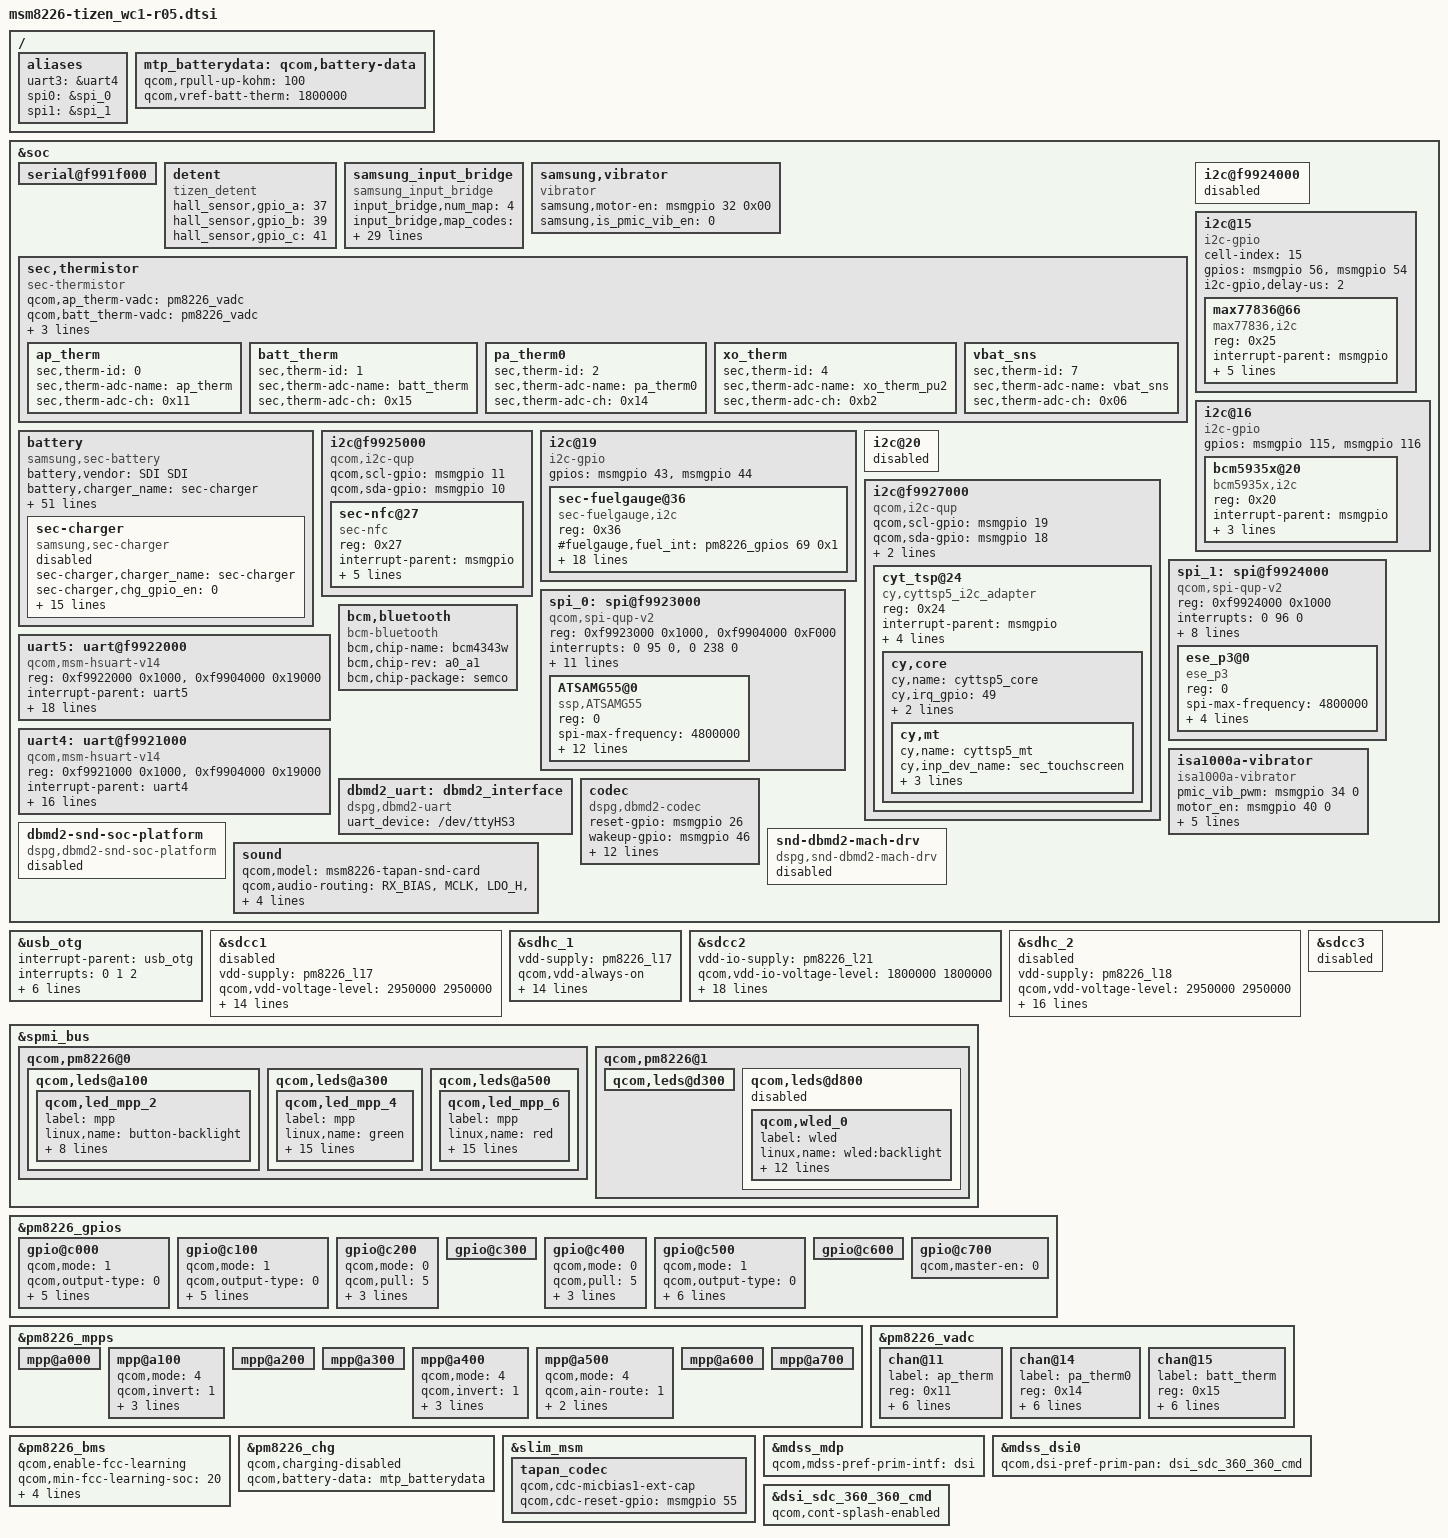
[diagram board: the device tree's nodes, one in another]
/* Copyright (c) 2013, The Linux Foundation. All rights reserved.
 *
 * This program is free software; you can redistribute it and/or modify
 * it under the terms of the GNU General Public License version 2 and
 * only version 2 as published by the Free Software Foundation.
 *
 * This program is distributed in the hope that it will be useful,
 * but WITHOUT ANY WARRANTY; without even the implied warranty of
 * MERCHANTABILITY or FITNESS FOR A PARTICULAR PURPOSE.  See the
 * GNU General Public License for more details.
 */

/{
	aliases {
		uart3 = &uart4;
		spi0 = &spi_0;
		spi1 = &spi_1;
	};
};

&soc {
	serial@f991f000 {
		status = "ok";
	};

	detent {
		compatible = "tizen_detent";
		hall_sensor,gpio_a = <37>;
		hall_sensor,gpio_b = <39>;
		hall_sensor,gpio_c = <41>;
	};

	samsung_input_bridge {
		compatible = "samsung_input_bridge";
		input_bridge,num_map = <4>;
		input_bridge,map_codes ="input_bridge,logdump_map_code",
					"input_bridge,safemode_map_code",
					"input_bridge,payment_map_code",
					"input_bridge,hall_log_map_code";
		input_bridge,map_types ="input_bridge,logdump_map_type",
					"input_bridge,safemode_map_type",
					"input_bridge,payment_map_type",
					"input_bridge,hall_log_map_type";
		input_bridge,logdump_map_code  = <115 114 115 114 116 114 115 116>;
		input_bridge,logdump_map_type  = <1 1 1 1 1 1 1 1>;
		input_bridge,safemode_map_code  = <114>;
		input_bridge,safemode_map_type  = <1>;
		input_bridge,payment_map_code  = <158>;
		input_bridge,payment_map_type  = <1>;
		input_bridge,hall_log_map_code = <116 8 8 8 8 8 8 8 8>;
		input_bridge,hall_log_map_type = <1 2 2 2 2 2 2 2 2>;
		input_bridge,env_str = "APPS_LOG", "SAFE_MODE", "PAYMENT", "APPS_LOG";
		input_bridge,env_value = "ON", "ON", "ON", "ON";
		input_bridge,map_key = <1>;
		input_bridge,enable_uevent = <1>;
		input_bridge,uevent_action = <2>;
		input_bridge,dev_num = <2>;
		input_bridge,dev_name_str = "qpnp_pon", "tizen_detent";
	};

	samsung,vibrator{
		compatible = "vibrator";
		samsung,motor-en = <&msmgpio 32 0x00>;
		samsung,is_pmic_vib_en = <0>;
		status = "ok";
	};

	sec,thermistor {
		compatible = "sec-thermistor";
		qcom,ap_therm-vadc	= <&pm8226_vadc>;
		qcom,batt_therm-vadc	= <&pm8226_vadc>;
		qcom,pa_therm0-vadc	= <&pm8226_vadc>;
		qcom,xo_therm_pu2-vadc	= <&pm8226_vadc>;
		qcom,vbat_sns-vadc	= <&pm8226_vadc>;
		ap_therm {
			sec,therm-id = <0>; /* SEC_THERM_AP */
			sec,therm-adc-name = "ap_therm";
			sec,therm-adc-ch = <0x11>; /* P_MUX_2_1_1 */
		};
		batt_therm {
			sec,therm-id = <1>; /* SEC_THERM_BATTERY */
			sec,therm-adc-name = "batt_therm";
			sec,therm-adc-ch = <0x15>; /* P_MUX_6_1_1 */
		};
		pa_therm0 {
			sec,therm-id = <2>; /* SEC_THERM_PAM0 */
			sec,therm-adc-name = "pa_therm0";
			sec,therm-adc-ch = <0x14>; /* P_MUX_5_1_1 */
		};
		xo_therm {
			sec,therm-id = <4>; /* SEC_THERM_XO */
			sec,therm-adc-name = "xo_therm_pu2";
			sec,therm-adc-ch = <0xb2>;
		};
		vbat_sns {
			sec,therm-id = <7>; /* SEC_THERM_VBAT_SNS */
			sec,therm-adc-name = "vbat_sns";
			sec,therm-adc-ch = <0x06>;
		};
	};

	battery {
		status = "okay";
		compatible = "samsung,sec-battery";
		battery,vendor = "SDI SDI";
		battery,charger_name = "sec-charger";
		battery,fuelgauge_name = "sec-fuelgauge";
		/* POWER_SUPPLY_TECHNOLOGY_LION */
		battery,technology = <2>;
		battery,bat_gpio_ta_nconnected = <2>;
		battery,chip_vendor = "QCOM";
		battery,bat_irq = <0>;
		battery,bat_irq_attr = <0>;
		/* SEC_BATTERY_CABLE_CHECK_CHGINT */
		battery,cable_check_type = <16>;
		/* SEC_BATTERY_CABLE_SOURCE_EXTERNAL */
		battery,cable_source_type = <1>;
		battery,event_check = <1>; /* true */
		battery,event_waiting_time = <180>;
		/* Monitor Setting */
		/* SEC_BATTERY_MONITOR_ALARM */
		battery,polling_type = <1>;
		battery,monitor_initial_count = <3>;
		/* SEC_BATTERY_CHECK_NONE */
		battery,battery_check_type = <0>;
		battery,check_count = <0>;
		battery,check_adc_max = <1440>;
		battery,check_adc_min = <0>;
		/* SEC_BATTERY_OVP_UVLO_CHGPOLLING */
		battery,ovp_uvlo_check_type = <3>;
		/* SEC_BATTERY_THERMAL_SOURCE_ADC */
		battery,thermal_source = <2>;
		battery,temp_adc_type = <1>; /* SEC_BATTERY_ADC_TYPE_AP */
		battery,adc_type = <0 1 1 1 1>; /* SEC_BATTERY_ADC_TYPE_AP */
		/* Basic - 10s, Charging - 30s, Dis-Charging - 30s,
		   30 - Not Charging, Sleep - 3600
		 */
		battery,polling_time = <10 30 30 30 3600>;
		battery,adc_check_count = <6>;
		/* battery,temp_table_adc = <27281 27669 28178 28724 29342
		   30101 30912 31807 32823 33858 34950 36049 37054 38025 38219
		   38448 38626 38795 38989 39229 39540 39687
		   39822 40523 41123 41619>;
		 */
		/* Temperature related information */
		/* SEC_BATTERY_TEMP_CHECK_NONE */
		battery,temp_check_type = <0>;
		battery,temp_check_count = <1>;
		battery,temp_high_threshold_event = <580>;
		battery,temp_high_recovery_event = <530>;
		battery,temp_low_threshold_event = <(-50)>;
		battery,temp_low_recovery_event = <0>;
		battery,temp_high_threshold_normal = <580>;
		battery,temp_high_recovery_normal = <530>;
		battery,temp_low_threshold_normal = <(-50)>;
		battery,temp_low_recovery_normal = <0>;

		battery,temp_high_threshold_lpm = <580>;
		battery,temp_high_recovery_lpm = <530>;
		battery,temp_low_threshold_lpm = <(-50)>;
		battery,temp_low_recovery_lpm = <0>;

		/* Battery - Charging Scenario */
		/* SEC_BATTERY_FULLCHARGED_CHGPSY */
		battery,full_check_type = <7>;
		/* SEC_BATTERY_FULLCHARGED_TIME */
		battery,full_check_type_2nd = <3>;
		battery,full_check_count = <1>;
		battery,chg_gpio_full_check = <0>;
		battery,chg_polarity_full_check = <1>;

		/* SEC_BATTERY_FULL_CONDITION_SOC |
		   SEC_BATTERY_FULL_CONDITION_NOTIMEFULL |
		   SEC_BATTERY_FULL_CONDITION_VCELL
		 */
		battery,full_condition_type = <13>;
		battery,full_condition_soc = <97>;
		battery,full_condition_vcell = <4300>;

		battery,recharge_check_count = <2>;
		/* SEC_BATTERY_RECHARGE_CONDITION_VCELL */
		battery,recharge_condition_type = <4>;
		battery,recharge_condition_soc = <90>;
		battery,recharge_condition_vcell = <4300>;

		battery,charging_total_time = <21600>; /* 6 Hours */
		battery,recharging_total_time = <5400>; /* 1.5 Hours */
		battery,charging_reset_time = <0>;

		/* Values need to be confirmed with the 8x26 H/W */
		/* Current related parameters need to be verified hence DT
		   for charger is not being used
		 */
		sec-charger{
			status = "disable";
			/* Charger */
			compatible = "samsung,sec-charger";
			sec-charger,charger_name = "sec-charger";
			sec-charger,chg_gpio_en = <0>;
			sec-charger,chg_polarity_en = <0>;
			sec-charger,chg_gpio_status = <0>;
			sec-charger,chg_polarity_status = <0>;
			sec-charger,chg_irq = <0>;
			sec-charger,chg_float_voltage = <4350>;
			/* SEC_BATTERY_OVP_UVLO_CHGPOLLING */
			sec-charger,ovp_uvlo_check_type = <3>;
			/* SEC_BATTERY_FULLCHARGED_CHGPSY */
			sec-charger,full_check_type = <7>;
			sec-charger,input_current_limit = <1800 460 460 1800 460
				900 1000 460 460 1000 650 1800 1800 460
				400 700 1300 300 1000 1800 460>;
			sec-charger,fast_charging_current = <2100 0 460 2100 460
				1200 1000 460 0 1200 750 2100 2100 0 400 700
				1300 300 1000 2100 0>;
			sec-charger,full_check_current_1st = <200 0 200 200 200
				200 200 200 0 200 200 200 200
				0 200 200 200 200 200 200 0>;
			sec-charger,full_check_current_2nd = <2400 0 2400 1800
				2400 2400 2400 2400 0 2400 2400
				2400 2400 0 2400 2400 2400 2400 2400 2400 0>;
		};
	};

	i2c@f9924000 {
	    status = "disable";
	};

	i2c@15{ /*BLSP-1 QUP-4*/
		/*MAX77836 Chip Node*/
		cell-index = <15>;
		compatible = "i2c-gpio";
		gpios = <&msmgpio 56 0  /*SDA*/
			&msmgpio 54 0 >;/*SCL*/
		i2c-gpio,delay-us = <2>;
		#address-cells = <1>;
		#size-cells = <0>;
		max77836@66 {
			compatible = "max77836,i2c";
			reg = <0x25>;
			interrupt-parent = <&msmgpio>;
			interrupts = <52 0>;
			max77836,irq-gpio = <&msmgpio 52 0x00>;
			max77836,irq-base = <353>;
			max77836,wc-irq-gpio = <0>;
			max77836,wakeup = <1>;
		};
	};

	i2c@16 {
		compatible = "i2c-gpio";
		gpios = <&msmgpio 115 0 /* sda */
			&msmgpio 116 0 /* scl */
			>;
		#address-cells = <1>;
		#size-cells = <0>;
		bcm5935x@20 {
			compatible = "bcm5935x,i2c";
			reg = <0x20>;
			interrupt-parent = <&msmgpio>;
			interrupts = <67 0>;
			bcm-wpc,irq-gpio = <&msmgpio 67 0x0>;
			bcm-wpc,detect_type = <0>;
		};
	};
	
	i2c@f9925000 {
		compatible = "qcom,i2c-qup";
		qcom,scl-gpio = <&msmgpio 11 0>;/* sda */
		qcom,sda-gpio = <&msmgpio 10 0>;/* scl */
		sec-nfc@27 {
			compatible = "sec-nfc";
			reg = <0x27>;
			interrupt-parent = <&msmgpio>;
			interrupts = <72 0>;
			sec-nfc,ven-gpio = <&msmgpio 45 0x0>;
			sec-nfc,firm-gpio = <&msmgpio 42 0x0>;
			sec-nfc,irq-gpio = <&msmgpio 72 0x0>;
			sec-nfc,pvdd-gpio = <&msmgpio 35 0x0>;
		};
	};

	i2c@19 {
		compatible = "i2c-gpio";
		gpios = <&msmgpio 43 0 /* sda */
			&msmgpio 44 0 /* scl */
			>;
		#address-cells = <1>;
		#size-cells = <0>;
		sec-fuelgauge@36 {
			compatible = "sec-fuelgauge,i2c";
			reg = <0x36>;
			#fuelgauge,fuel_int = <&pm8226_gpios 69 0x1>;
			interrupt-parent = <&msmgpio>;
			interrupts = <69 0>;
			fuelgauge,fuel_int = <&msmgpio 69 0x0>;
			fuelgauge,fg_irq = <&msmgpio 69 0x0>;
			/* IRQF_TRIGGER_RISING */
			fg_irq_attr = <1>;
			fuelgauge,fuel_alert_soc = <2>;
			fuelgauge,repeated_fuelalert = <0>;
			/* fuelgauge,bat_int = <&pm8226_mpps 8 0>; */
			fuelgauge,bat_irq = <0>;
			/* .capacity_calculation_type =
			   SEC_FUELGAUGE_CAPACITY_TYPE_RAW |
			   SEC_FUELGAUGE_CAPACITY_TYPE_SCALE |
			   SEC_FUELGAUGE_CAPACITY_TYPE_DYNAMIC_SCALE |
			   SEC_FUELGAUGE_CAPACITY_TYPE_SKIP_ABNORMAL,
			 */
			/* fuelgauge,capacity_calculation_type = <0x17>; */
			fuelgauge,capacity_calculation_type = <0x07>;
			fuelgauge,capacity_max = <1000>;
			fuelgauge,capacity_max_margin = <50>;
			fuelgauge,capacity_min = <5>;
			/*
			   fuelgauge,rcomp0 = <0x7B>;
			   fuelgauge,rcomp_charging = <0x79>;
			 */
			fuelgauge,rcomp0 = <0x4A>;
			fuelgauge,rcomp_charging = <0x4A>;
			fuelgauge,temp_cohot = <0xFFFFFAD2>; 	/* -1325 */
			fuelgauge,temp_cocold = <0xFFFFE93E>;	/* -5825 */
			/* using 19 bits as recommended by Maxim */
			fuelgauge,is_using_model_data = <1>;
			fuelgauge,type_str = "SDI";
		};
	};

	i2c@20 {
		status="disabled";
	};

	i2c@f9927000{ /* BLSP1 QUP5 Hardware ID BLSP5 */
		compatible = "qcom,i2c-qup";
		qcom,scl-gpio = <&msmgpio 19 0>;
		qcom,sda-gpio = <&msmgpio 18 0>;
		qcom,i2c-bus-freq = <400000>;
		qcom,clk-ctl-xfer;
		cyt_tsp@24 {
			compatible = "cy,cyttsp5_i2c_adapter";
			reg = <0x24>; /*slave address*/
			interrupt-parent = <&msmgpio>;
			interrupts = <49 0>;
			vddo-supply = <&pm8226_l28>;
			avdd-supply = <&pm8226_l19>;

			cy,adapter_id = "cyttsp5_i2c_adapter";
			cy,core {
				cy,name = "cyttsp5_core";
				cy,irq_gpio = <49>;
				cy,hid_desc_register = <1>;
				cy,report_rate = <90>;
				cy,mt {
					cy,name = "cyttsp5_mt";
					cy,inp_dev_name = "sec_touchscreen";
					cy,flags = <0x00>;
					cy,abs =
						/* ABS_MT_POSITION_X, CY_ABS_MIN_X, CY_ABS_MAX_X, 0, 0 */
						<0x35 0 360 0 0
						/* ABS_MT_POSITION_Y, CY_ABS_MIN_Y, CY_ABS_MAX_Y, 0, 0 */
						0x36 0 360 0 0
						/* ABS_MT_PRESSURE, CY_ABS_MIN_P, CY_ABS_MAX_P, 0, 0 */
						0x3a 0 255 0 0
						/* CY_IGNORE_VALUE, CY_ABS_MIN_W, CY_ABS_MAX_W, 0, 0 */
						0xffff 0 255 0 0
						/* ABS_MT_TRACKING_ID, CY_ABS_MIN_T, CY_ABS_MAX_T, 0, 0 */
						0x39 0 15 0 0
						/* ABS_MT_TOUCH_MAJOR, 0, 255, 0, 0 */
						0x30 0 255 0 0
						/* ABS_MT_TOUCH_MINOR, 0, 255, 0, 0 */
						0x31 0 255 0 0
						/* ABS_MT_ORIENTATION, -128, 127, 0, 0 */
						0x34 0xfffffed7 127 0 0
						/* ABS_MT_TOOL_TYPE, 0, MT_TOOL_MAX, 0, 0 */
						0x37 0 1 0 0>;
				};
			};
		};
	};

	spi_0: spi@f9923000 { /* BLSP1 BLSP1_QUP0*/
		compatible = "qcom,spi-qup-v2";
		#address-cells = <1>;
		#size-cells = <0>;
		reg-names = "spi_physical", "spi_bam_physical";
		reg = <0xf9923000 0x1000>,
			<0xf9904000 0xF000>;
		interrupt-names = "spi_irq", "spi_bam_irq";
		interrupts = <0 95 0>, <0 238 0>;
		spi-max-frequency = <19200000>;

		qcom,gpio-mosi = <&msmgpio 0 0>;
		qcom,gpio-miso = <&msmgpio 1 0>;
		qcom,gpio-clk  = <&msmgpio 3 0>;
		qcom,gpio-cs0  = <&msmgpio 2 0>;

		qcom,infinite-mode = <0>;
		qcom,use-bam;
		qcom,ver-reg-exists;
		qcom,bam-consumer-pipe-index = <12>;
		qcom,bam-producer-pipe-index = <13>;
		qcom,master-id = <86>;

		ATSAMG55@0 {
			compatible = "ssp,ATSAMG55";
			reg = <0>;
			spi-max-frequency = <4800000>;
			interrupt-parent = <&msmgpio>;
			interrupts = <106 0>;
			ssp,mcu_int1-gpio = <&msmgpio 106 0x00>;
			ssp,mcu_int2-gpio = <&msmgpio 107 0x00>;
			ssp,ap_int-gpio = <&msmgpio 108 0x00>;
			ssp,rst-gpio = <&msmgpio 28 0x00>;
			ssp,acc-position = <4>;
			ssp,mag-position = <2>;
			ssp,ap-rev=<5>;
			ssp,fw_name = "ssp_wc1-l.fw";
			ssp,ums_fw_name = "ssp_at.bin";
			ssp,mcu_vreg-supply = <&pm8226_lvs1>;
		};
	};

        spi_1: spi@f9924000 { /* BLSP2 BLSP1_QUP1*/
                compatible = "qcom,spi-qup-v2";
                #address-cells = <1>;
                #size-cells = <0>;
                reg-names = "spi_physical";
                reg = <0xf9924000 0x1000>;
                interrupt-names = "spi_irq";
                interrupts = <0 96 0>;
                spi-max-frequency = <19200000>;

                qcom,gpio-mosi = <&msmgpio 4 0>;
                qcom,gpio-miso = <&msmgpio 5 0>;
                qcom,gpio-clk  = <&msmgpio 7 0>;
                qcom,gpio-cs0  = <&msmgpio 6 0>;

                qcom,infinite-mode = <0>;
                qcom,ver-reg-exists;
                qcom,master-id = <86>;

		ese_p3@0 {
		    compatible = "ese_p3";
		    reg = <0>;
		    spi-max-frequency = <4800000>;
		    p3-cs-gpio = <&msmgpio 6 0>;
		    p3-clk-gpio = <&msmgpio 7 0>;
		    p3-mosi-gpio = <&msmgpio 4 0>;
		    p3-miso-gpio = <&msmgpio 5 0>;
		};
	};


	uart5: uart@f9922000 { /* BLSP1 UART5 : HW ID BLSP6 */
		       compatible = "qcom,msm-hsuart-v14";
		       status = "ok";
		       reg = <0xf9922000 0x1000>,
			   <0xf9904000 0x19000>;
		       reg-names = "core_mem", "bam_mem";
		       interrupt-names = "core_irq", "bam_irq", "wakeup_irq";
		#address-cells = <0>;
		       interrupt-parent = <&uart5>;
		       interrupts = <0 1 2>;
		#interrupt-cells = <1>;
		       interrupt-map-mask = <0xffffffff>;
		       interrupt-map = <0 &intc 0 112 0
			       1 &intc 0 238 0
			       2 &msmgpio 21 0>;
		       qcom,tx-gpio = <&msmgpio 20 0x00>;
		       qcom,rx-gpio = <&msmgpio 21 0x00>;
		       qcom,cts-gpio = <&msmgpio 22 0x00>;
		       qcom,rfr-gpio = <&msmgpio 23 0x00>;
		       qcom,inject-rx-on-wakeup = <1>;
		       qcom,rx-char-to-inject = <0xFD>;
		       qcom,msm-obs = <1>; /* for case 01545094 */

		       qcom,bam-tx-ep-pipe-index = <10>;		/*Consumer pipe*/
		       qcom,bam-rx-ep-pipe-index = <11>;		/*Producer pipe*/
		       qcom,msm-bus,name = "uart5";
		       qcom,msm-bus,num-cases = <2>;
		       qcom,msm-bus,num-paths = <1>;
		       qcom,msm-bus,vectors-KBps = <86 512 0 0>,
			       <86 512 500 800>;
	};

	uart4: uart@f9921000 { /* BLSP1 UART4 : HW ID BLSP5 */
			compatible = "qcom,msm-hsuart-v14";
			status = "ok";
			reg = <0xf9921000 0x1000>,
				<0xf9904000 0x19000>;
			reg-names = "core_mem", "bam_mem";
			interrupt-names = "core_irq", "bam_irq", "wakeup_irq";
			#address-cells = <0>;
			interrupt-parent = <&uart4>;
			interrupts = <0 1 2>;
			#interrupt-cells = <1>;
			interrupt-map-mask = <0xffffffff>;
			interrupt-map = <0 &intc 0 111 0 1 &intc 0 238 0 2 &msmgpio 17 0>;
			qcom,tx-gpio = <&msmgpio 16 0x00>;
			qcom,rx-gpio = <&msmgpio 17 0x00>;
			qcom,inject-rx-on-wakeup = <1>;
			qcom,rx-char-to-inject = <0xFD>;
			qcom,msm-obs = <1>; /* for case 01545094 */
			qcom,bam-tx-ep-pipe-index = <8>;
			qcom,bam-rx-ep-pipe-index = <9>;
			qcom,msm-bus,name = "uart4";
			qcom,msm-bus,num-cases = <2>;
			qcom,msm-bus,num-paths = <1>;
			qcom,msm-bus,vectors-KBps = <86 512 0 0>, <86 512 500 800>;
	};

	isa1000a-vibrator {
		status = "okay";
		compatible = "isa1000a-vibrator";
		pmic_vib_pwm = <&msmgpio 34 0>;
		motor_en = <&msmgpio 40 0>;
		/*compatible = "vibrator";*/
		pinctrl-names = "default";
		haptic,max_timeout = <10000>;
		haptic,duty = <32580>;
		haptic,period = <33244>;
		haptic,pwm_id = <0>;
		/*haptic,regulator_name = "VDD_MOTOR_3V0";*/
		haptic,regulator_name = "mot_3.3v";
	};

	bcm,bluetooth {
		compatible = "bcm-bluetooth";
		bcm,chip-name = "bcm4343w";
		bcm,chip-rev = "a0_a1";
		bcm,chip-package = "semco";
	};

	dbmd2_uart: dbmd2_interface {
		status = "okay";
		compatible = "dspg,dbmd2-uart";
		uart_device = "/dev/ttyHS3";
	};

	codec {
		status = "okay";
		compatible = "dspg,dbmd2-codec";
		reset-gpio = <&msmgpio 26 0>;
		wakeup-gpio = <&msmgpio 46 0>; /* chip enable */
		sv-gpio = <&msmgpio 27 0>; /* voice interrupt */

		cmd-interface = <&dbmd2_uart>;
		feature-va; /* enable VA */
		va-firmware-name = "dbmd2_va_fw.bin";
		va-config = <0x80220103
				0x8015008a
				0x801b0020
				0x80210000
				0x80290001
				0x80230040
				0x8016000a
				0x80280301>;
		va-speeds = <0x0301 57600 0 0
			     0x0000 1000000 0 0
			     0x0000 1000000 0 0>;

		va-mic-config = <0x0001 0x0002 0x004d>;
		va-mic-mode = <4>;
		auto_detection = <1>;
		master-clk-rate = <32768>;
	};

	dbmd2-snd-soc-platform {
		status = "disable";
		compatible = "dspg,dbmd2-snd-soc-platform";
	};

	snd-dbmd2-mach-drv {
		status = "disable";
		compatible = "dspg,snd-dbmd2-mach-drv";
	};

	sound {
		qcom,model = "msm8226-tapan-snd-card";
		qcom,audio-routing =
			"RX_BIAS", "MCLK",
			"LDO_H", "MCLK",
			"SPK_OUT", "MCLK",
			"SPK_OUT", "EXT_VDD_SPKR",
			"AMIC1", "External LDO",
			"External LDO", "Main Mic";

		qcom,cdc-mclk-gpios = <&pm8226_gpios 1 0>;
		qcom,micbias-en-gpio = <&pm8226_gpios 6 0>;
		/*qcom,cdc-vdd-spkr-gpios = <&pm8226_gpios 2 0>;*/
	};
};

&usb_otg {
	#address-cells = <0>;
	interrupt-parent = <&usb_otg>;
	interrupts = <0 1 2>;
	#interrupt-cells = <1>;
	interrupt-map-mask = <0xffffffff>;
	interrupt-map = <0 &intc 0 134 0
			1 &intc 0 140 0
			2 &spmi_bus 0x0 0x0 0x9 0x0>;
	interrupt-names = "core_irq", "async_irq", "pmic_id_irq";

	qcom,hsusb-otg-mode = <1>;
	qcom,hsusb-otg-otg-control = <2>;
	vbus_otg-supply = <&pm8226_chg_otg>;
};

&sdcc1 {
	vdd-supply = <&pm8226_l17>;
	qcom,vdd-voltage-level = <2950000 2950000>;
	qcom,vdd-current-level = <800 500000>;

	vdd-io-supply = <&pm8226_l6>;
	qcom,vdd-io-always-on;
	qcom,vdd-io-voltage-level = <1800000 1800000>;
	qcom,vdd-io-current-level = <250 154000>;

	qcom,pad-pull-on = <0x0 0x3 0x3>; /* no-pull, pull-up, pull-up */
	qcom,pad-pull-off = <0x0 0x3 0x3>; /* no-pull, pull-up, pull-up */
	qcom,pad-drv-on = <0x4 0x4 0x4>; /* 10mA, 10mA, 10mA */
	qcom,pad-drv-off = <0x0 0x0 0x0>; /* 2mA, 2mA, 2mA */

	qcom,clk-rates = <400000 25000000 50000000 100000000 200000000>;
	qcom,sup-voltages = <2950 2950>;

	qcom,bus-speed-mode = "HS200_1p8v", "DDR_1p8v";
	qcom,nonremovable;

	status = "disabled";
};

&sdhc_1 {
	vdd-supply = <&pm8226_l17>;
	qcom,vdd-always-on;
	qcom,vdd-voltage-level = <2950000 2950000>;
	qcom,vdd-current-level = <800 500000>;

	vdd-io-supply = <&pm8226_l6>;
	qcom,vdd-io-always-on;
	qcom,vdd-io-voltage-level = <1800000 1800000>;
	qcom,vdd-io-current-level = <250 154000>;

	qcom,pad-pull-on = <0x0 0x3 0x3>; /* no-pull, pull-up, pull-up */
	qcom,pad-pull-off = <0x0 0x3 0x3>; /* no-pull, pull-up, pull-up */
	qcom,pad-drv-on = <0x4 0x4 0x4>; /* 10mA, 10mA, 10mA */
	qcom,pad-drv-off = <0x0 0x0 0x0>; /* 2mA, 2mA, 2mA */

	qcom,clk-rates = <400000 25000000 50000000 100000000 200000000>;
	qcom,bus-speed-mode = "HS200_1p8v", "DDR_1p8v";
	qcom,nonremovable;

	status = "ok";
};

&sdcc2 {
	vdd-io-supply = <&pm8226_l21>;
	qcom,vdd-io-voltage-level = <1800000 1800000>;
	qcom,vdd-io-current-level = <2000 16000>;
	qcom,vdd-io-always-on;

	qcom,pad-pull-on = <0x0 0x3 0x3>; /* no-pull, pull-up, pull-up */
	qcom,pad-pull-off = <0x0 0x3 0x3>; /* no-pull, pull-up, pull-up */
	qcom,pad-drv-on = <0x4 0x4 0x4>; /* 10mA, 10mA, 10mA */
	qcom,pad-drv-off = <0x0 0x0 0x0>; /* 2mA, 2mA, 2mA */

	qcom,clk-rates = <400000 25000000 50000000 100000000 200000000>;
	qcom,sup-voltages = <2950 2950>;

	qcom,xpc;
	qcom,bus-speed-mode = "SDR12", "SDR25", "SDR50", "DDR50", "SDR104";
	qcom,current-limit = <600>; #address-cells = <0>; interrupt-parent = <&sdcc2>;
	interrupts = <0 1 2>;
	#interrupt-cells = <1>;
	interrupt-map-mask = <0xffffffff>;
	interrupt-map = <0 &intc 0 125 0
			1 &intc 0 220 0>;
	interrupt-names = "core_irq", "bam_irq";
	status-cb = <2>;

	status = "ok";
};

&sdhc_2 {
	vdd-supply = <&pm8226_l18>;
	qcom,vdd-voltage-level = <2950000 2950000>;
	qcom,vdd-current-level = <9000 800000>;

	vdd-io-supply = <&pm8226_l21>;
	qcom,vdd-io-voltage-level = <1800000 2950000>;
	qcom,vdd-io-current-level = <6 22000>;

	qcom,pad-pull-on = <0x0 0x3 0x3>; /* no-pull, pull-up, pull-up */
	qcom,pad-pull-off = <0x0 0x3 0x3>; /* no-pull, pull-up, pull-up */
	qcom,pad-drv-on = <0x4 0x4 0x4>; /* 10mA, 10mA, 10mA */
	qcom,pad-drv-off = <0x0 0x0 0x0>; /* 2mA, 2mA, 2mA */

	qcom,clk-rates = <400000 25000000 50000000 100000000 200000000>;

	#address-cells = <0>;
	interrupt-parent = <&sdhc_2>;
	interrupts = <0 1 2>;
	#interrupt-cells = <1>;
	interrupt-map-mask = <0xffffffff>;
	interrupt-map = <0 &intc 0 125 0
			1 &intc 0 221 0
			2 &msmgpio 38 0x3>;
	interrupt-names = "hc_irq", "pwr_irq", "status_irq";
	cd-gpios = <&msmgpio 38 0x1>;

	status = "disabled";
};

&sdcc3 {
	status = "disabled";
};

&spmi_bus {
	qcom,pm8226@0 {
		qcom,leds@a100 {
			status = "okay";
			qcom,led_mpp_2 {
				label = "mpp";
				linux,name = "button-backlight";
				linux,default-trigger = "none";
				qcom,default-state = "off";
				qcom,max-current = <40>;
				qcom,current-setting = <5>;
				qcom,id = <6>;
				qcom,mode = "manual";
				qcom,source-sel = <1>;
				qcom,mode-ctrl = <0x60>;
			};
		};

		qcom,leds@a300 {
			status = "okay";
			qcom,led_mpp_4 {
				label = "mpp";
				linux,name = "green";
				linux,default-trigger = "battery-full";
				qcom,default-state = "off";
				qcom,max-current = <40>;
				qcom,current-setting = <5>;
				qcom,id = <6>;
				qcom,mode = "pwm";
				qcom,pwm-us = <1000>;
				qcom,source-sel = <8>;
				qcom,mode-ctrl = <0x60>;
				qcom,pwm-channel = <0>;
				qcom,start-idx = <1>;
				qcom,ramp-step-ms = <120>;
				qcom,duty-pcts = [00 00 00 00 00
						  00 00 00 00 00
						  50 00 00 00 00
						  00 00 00 00 00
						  00];
				qcom,use-blink;
			};
		};

		qcom,leds@a500 {
			status = "okay";
			qcom,led_mpp_6 {
				label = "mpp";
				linux,name = "red";
				linux,default-trigger = "battery-charging";
				qcom,default-state = "off";
				qcom,max-current = <40>;
				qcom,current-setting = <5>;
				qcom,id = <6>;
				qcom,mode = "pwm";
				qcom,pwm-us = <1000>;
				qcom,mode-ctrl = <0x60>;
				qcom,source-sel = <10>;
				qcom,pwm-channel = <5>;
				qcom,start-idx = <1>;
				qcom,ramp-step-ms = <120>;
				qcom,duty-pcts = [00 00 00 00 00
						  00 00 00 00 00
						  50 00 00 00 00
						  00 00 00 00 00
						  00];
				qcom,use-blink;
			};
		};
	};

	qcom,pm8226@1 {
		qcom,leds@d300 {
			status = "okay";
		};

		qcom,leds@d800 {
			status = "disabled"; /*If WLED is not used for Backlight control*/
			qcom,wled_0 {		/*for TFT Panel, this to be disabled */
				label = "wled";
				linux,name = "wled:backlight";
				linux,default-trigger = "bkl-trigger";
				qcom,cs-out-en;
				qcom,op-fdbck = <1>;
				qcom,default-state = "off";
				qcom,max-current = <20>;
				qcom,ctrl-delay-us = <0>;
				qcom,boost-curr-lim = <3>;
				qcom,cp-sel = <0>;
				qcom,switch-freq = <11>;
				qcom,ovp-val = <0>;
				qcom,num-strings = <1>;
				qcom,id = <0>;
			};
		};
	};
};

&pm8226_gpios {
	gpio@c000 { /* GPIO 1 */
		/* XO_PMIC_CDC_MCLK enable for tapan codec */
		qcom,mode = <1>;		/* Digital output */
		qcom,output-type = <0>;	/* CMOS logic */
		qcom,pull = <5>;		/* QPNP_PIN_PULL_NO*/
		qcom,vin-sel = <3>;		/* QPNP_PIN_VIN3 */
		qcom,out-strength = <3>;/* QPNP_PIN_OUT_STRENGTH_HIGH */
		qcom,src-sel = <2>;		/* QPNP_PIN_SEL_FUNC_1 */
		qcom,master-en = <1>;	/* Enable GPIO */
	};

	gpio@c100 { /* GPIO 2 */
		qcom,mode = <1>;
		qcom,output-type = <0>;
		qcom,pull = <5>;
		qcom,vin-sel = <3>;
		qcom,out-strength = <3>;
		qcom,src-sel = <2>;
		qcom,master-en = <1>;
	};

	gpio@c200 { /* GPIO 3 */
		qcom,mode = <0>;		/* Digital intput */
		/*qcom,output-type = <0>;*/
		/* CMOS logic */
		qcom,pull = <5>;		/* QPNP_PIN_PULL_NO*/
		qcom,vin-sel = <2>;		/* QPNP_PIN_VIN3 */ /*3*/
		qcom,src-sel = <2>;		/* QPNP_PIN_SEL_FUNC_1 */
		qcom,master-en = <1>;	/* Enable GPIO */
	};

	gpio@c300 { /* GPIO 4 */
	};

	gpio@c400 { /* GPIO 5 */
		qcom,mode = <0>;		/* QPNP_PIN_MODE_DIG_IN */
		qcom,pull = <5>;		/* QPNP_PIN_PULL_NO */
		qcom,vin-sel = <2>;		/* QPNP_PIN_VIN2 */
		qcom,src-sel = <2>;		/* QPNP_PIN_SEL_FUNC_1 */
		qcom,master-en = <1>;
	};

	gpio@c500 { /* GPIO 6 */
		qcom,mode = <1>;                /* Digital output */
		qcom,output-type = <0>;         /* CMOS logic */
		qcom,pull = <5>;                /* QPNP_PIN_PULL_NO */
		qcom,invert = <0>;              /* Output low initially */
		qcom,vin-sel = <2>;             /* S3 = 1.8 V */
		qcom,src-sel = <0>;             /* Constant */
		qcom,out-strength = <2>;        /* Medium drive strength */
		qcom,master-en = <1>;           /* Enable GPIO */
	};

	gpio@c600 { /* GPIO 7 */
	};

	gpio@c700 { /* GPIO 8 */
		qcom,master-en = <0>;
	};
};

&pm8226_mpps {
	mpp@a000 { /* MPP 1 */
	};

	mpp@a100 { /* MPP 2 */
		/* AP_THERM config */
		qcom,mode = <4>; /* AIN input */
		qcom,invert = <1>; /* Enable MPP */
		qcom,ain-route = <1>; /* AMUX 6 */
		qcom,master-en = <1>;
		qcom,src-sel = <0>; /* Function constant */
	};

	mpp@a200 { /* MPP 3 */
	};

	mpp@a300 { /* MPP 4 */
	};

	mpp@a400 { /* MPP 5 */
		/* PA_THERM0 config */
		qcom,mode = <4>; /* AIN input */
		qcom,invert = <1>; /* Enable MPP */
		qcom,ain-route = <0>; /* AMUX 5 */
		qcom,master-en = <1>;
		qcom,src-sel = <0>; /* Function constant */
	};

	mpp@a500 { /* MPP 6 */
		/* BATT_THERM config */
		qcom,mode = <4>; /* AIN input */
		qcom,ain-route = <1>; /* AMUX 6 */
		qcom,master-en = <1>;
		qcom,src-sel = <0>; /* Function constant */
	};

	mpp@a600 { /* MPP 7 */
	};

	mpp@a700 { /* MPP 8 */
	};
};

&pm8226_vadc {
	chan@11 {
		label = "ap_therm";
		reg = <0x11>;
		qcom,decimation = <0>;
		qcom,pre-div-channel-scaling = <0>;
		qcom,calibration-type = "ratiometric";
		qcom,scale-function = <2>;
		qcom,hw-settle-time = <2>;
		qcom,fast-avg-setup = <0>;
	};

	chan@14 {
		label = "pa_therm0";
		reg = <0x14>;
		qcom,decimation = <0>;
		qcom,pre-div-channel-scaling = <0>;
		qcom,calibration-type = "ratiometric";
		qcom,scale-function = <10>;
		qcom,hw-settle-time = <2>;
		qcom,fast-avg-setup = <0>;
	};

	chan@15 {
		label = "batt_therm";
		reg = <0x15>;
		qcom,decimation = <0>;
		qcom,pre-div-channel-scaling = <0>;
		qcom,calibration-type = "ratiometric";
		qcom,scale-function = <2>;
		qcom,hw-settle-time = <2>;
		qcom,fast-avg-setup = <0>;
	};
};

/ {
	mtp_batterydata: qcom,battery-data {
		qcom,rpull-up-kohm = <100>;
		qcom,vref-batt-therm = <1800000>;

		/include/ "batterydata-palladium.dtsi"
		/include/ "batterydata-mtp-3000mah.dtsi"
	};
};

&pm8226_bms {
	status = "ok";
	qcom,enable-fcc-learning;
	qcom,min-fcc-learning-soc = <20>;
	qcom,min-fcc-ocv-pc = <30>;
	qcom,min-fcc-learning-samples = <5>;
	qcom,fcc-resolution = <10>;
	qcom,battery-data = <&mtp_batterydata>;
};

&pm8226_chg {
	qcom,charging-disabled;
	qcom,battery-data = <&mtp_batterydata>;
};

&slim_msm {
	tapan_codec {
		qcom,cdc-micbias1-ext-cap;
		qcom,cdc-reset-gpio = <&msmgpio 55 0>;
	};
};

&mdss_mdp {
	qcom,mdss-pref-prim-intf = "dsi";
};

&mdss_dsi0 {
	qcom,dsi-pref-prim-pan = <&dsi_sdc_360_360_cmd>;
};

&dsi_sdc_360_360_cmd {
	qcom,cont-splash-enabled;
};
